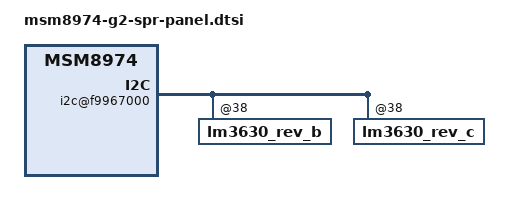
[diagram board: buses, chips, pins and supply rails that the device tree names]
/* Copyright (c) 2012, Code Aurora Forum. All rights reserved.
 *
 * This program is free software; you can redistribute it and/or modify
 * it under the terms of the GNU General Public License version 2 and
 * only version 2 as published by the Free Software Foundation.
 *
 * This program is distributed in the hope that it will be useful,
 * but WITHOUT ANY WARRANTY; without even the implied warranty of
 * MERCHANTABILITY or FITNESS FOR A PARTICULAR PURPOSE.  See the
 * GNU General Public License for more details.
 */

&mdss_dsi0 {
	qcom,platform-lane-config = [00 00 00 00 00 00 00 01 c8
			00 00 00 00 05 00 00 01 c8
			00 00 00 00 0a 00 00 01 c8
			00 00 00 00 0f 00 00 01 c8
			00 c0 00 00 00 00 00 01 bb];
	qcom,dsi-pref-prim-pan = <&mdss_dsi_g2_lgd_cmd>;
	qcom,platform-supply-entry2 {
		qcom,supply-enable-load = <300000>;
	};
};

&mdss_dsi_g2_lgd_cmd {
	qcom,mdss-dsi-panel-clock-rate = <893952000>;
};

&mdss_dsi_g2_jdi_cmd {
	qcom,mdss-dsi-panel-clock-rate = <893952000>;
};

&soc {
	i2c@f9967000 {
		lm3630_rev_b@38 {
			status = "ok";
			lm3630,enable_pwm = <1>;
			lm3630,blmap = <
				2 2 2 2 2 2 2 2 2 2 2 2 2 2 2
				2 2 2 2 2 2 2 2 2 2 2 2 2 2 2
				2 2 2 2 2 2 2 2 3 3 3 3 3 3 3
				3 3 3 3 3 3 3 3 3 3 3 3 3 3 3
				3 3 3 3 4 4 4 4 4 4 4 4 5 5 5
				5 5 5 6 6 6 6 6 6 6 6 7 7 7 7
				8 8 9 9 9 10 10 10 10 11 11 11 12 12 12
				13 13 13 14 14 17 17 17 18 18 19 19 20 20 21
				21 22 22 23 23 24 24 25 25 26 27 27 28 28 28
				34 34 34 35 35 35 36 36 36 37 37 38 38 39 39
				40 41 42 43 43 44 45 46 47 48 49 50 51 51 52
				53 54 55 56 57 58 59 60 61 63 64 65 66 67 68
				69 70 72 73 74 75 76 78 79 80 82 83 84 85 87
				88 90 91 92 94 95 97 98 100 101 103 104 106 107 109
				110 112 114 115 117 119 120 122 124 126 127 129 131 133 134
				136 138 140 142 144 146 148 150 152 154 156 158 160 162 164
				166 168 170 173 175 177 179 181 184 186 188 191 193 195 198 200>;
			revision = "...rev_a";
		};

		lm3630_rev_c@38 {
			status = "ok";
			lm3630,enable_pwm = <1>;
			lm3630,blmap = <
				2 2 2 2 2 2 2 2 2 2 2 2 2 2 2
				2 2 2 2 2 2 2 2 2 2 2 2 2 2 2
				2 2 2 2 2 2 2 2 3 3 3 3 3 3 3
				3 3 3 3 3 3 3 3 3 3 3 3 3 3 3
				3 3 3 3 4 4 4 4 4 4 4 4 5 5 5
				5 5 5 6 6 6 6 6 6 6 6 7 7 7 7
				8 8 9 9 9 10 10 10 10 11 11 11 12 12 12
				13 13 13 14 14 17 17 17 18 18 19 19 20 20 21
				21 22 22 23 23 24 24 25 25 26 27 27 28 28 28
				34 34 34 35 35 35 36 36 36 37 37 38 38 39 39
				40 41 42 43 43 44 45 46 47 48 49 50 51 51 52
				53 54 55 56 57 58 59 60 61 63 64 65 66 67 68
				69 70 72 73 74 75 76 78 79 80 82 83 84 85 87
				88 90 91 92 94 95 97 98 100 101 103 104 106 107 109
				110 112 114 115 117 119 120 122 124 126 127 129 131 133 134
				136 138 140 142 144 146 148 150 152 154 156 158 160 162 164
				166 168 170 173 175 177 179 181 184 186 188 191 193 195 198 200>;
			revision = "rev_b...";
		};
	};
};
